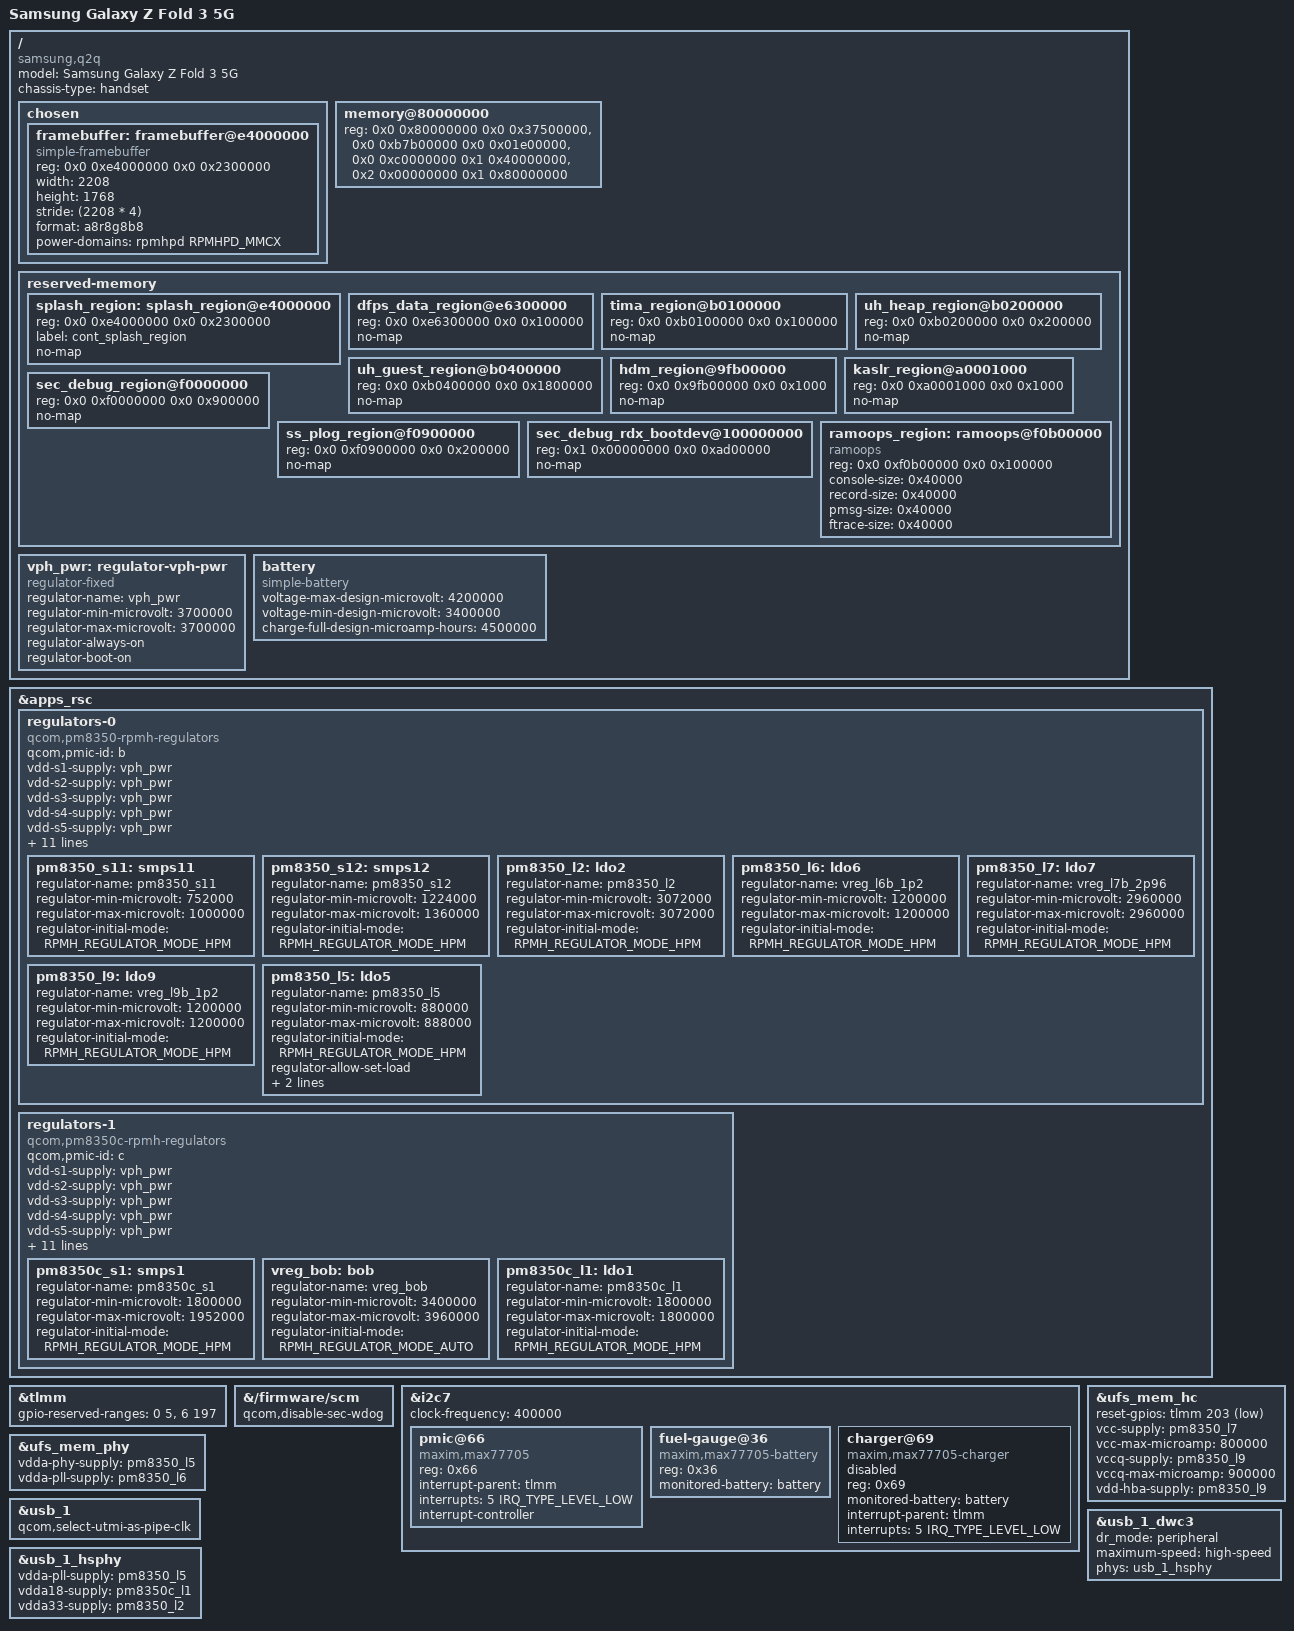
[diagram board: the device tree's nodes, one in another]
// SPDX-License-Identifier: BSD-3-Clause
/*
 * Samsung Galaxy Z Fold 3 5G (SM-F926B, codename q2q)
 * SoC: Qualcomm SM8350 (lahaina)
 *
 * STAGE 1: deliberately minimal. Boots to an initramfs with a framebuffer
 * console and USB gadget, nothing else. UFS, DSI, Wi-Fi, audio and the
 * remoteprocs all come later -- the point of this file is the smallest thing
 * that can possibly boot, so that a failure has few candidate causes.
 *
 * Modelled on two upstream files:
 *   sm8350-sony-xperia-sagami.dtsi  -- correct SM8350 rails and PMIC labels
 *   sm8450-samsung-r0q.dts          -- Samsung conventions (splash_region, USB 2.0)
 *
 * Board data was read off the device on 2026-11-07, not guessed:
 *   /memory             the four ranges ABL itself publishes (11.90 GiB, 12 GB unit)
 *   reserved-memory     37 regions from the merged post-ABL DT
 *   framebuffer         cont_splash_region + the S6E3XA2 panel timings
 *   ro.revision = 9  ->  board DTS revision r08 is authoritative for this unit
 *
 * NOT BOOTED. NOT TESTED. See dts-work/README.md.
 */

/dts-v1/;

#include <dt-bindings/gpio/gpio.h>
#include <dt-bindings/interrupt-controller/arm-gic.h>
#include <dt-bindings/regulator/qcom,rpmh-regulator.h>

#include "sm8350.dtsi"
#include "pm8350.dtsi"
#include "pm8350c.dtsi"

/ {
	model = "Samsung Galaxy Z Fold 3 5G";
	compatible = "samsung,q2q", "qcom,sm8350";
	chassis-type = "handset";

	/*
	 * ABL hands us no command line (uniLoader owns it, and the stock one is
	 * console=null anyway), so force our own in the kernel config with
	 * CONFIG_CMDLINE_FORCE.
	 */
	chosen {
		#address-cells = <2>;
		#size-cells = <2>;
		ranges;

		/*
		 * The bootloader's continuous-splash surface. Lets us have a visible
		 * console with no display driver at all -- there is no UART on this
		 * device, so this is the primary debug output for first boot.
		 *
		 * The inner panel is NATIVELY LANDSCAPE (2208x1768). Text will appear
		 * rotated relative to how the device is held; that is expected.
		 */
		framebuffer: framebuffer@e4000000 {
			compatible = "simple-framebuffer";
			reg = <0x0 0xe4000000 0x0 0x2300000>;
			width = <2208>;
			height = <1768>;
			stride = <(2208 * 4)>;
			format = "a8r8g8b8";

			/*
			 * Hold the display power domain up.
			 *
			 * The Galaxy Tab S8+ port warns that simplefb needs `clocks`
			 * and `power-domains` or the bootloader's scanout gets torn
			 * down. Only half of that applies to us:
			 *
			 *  - clocks: deliberately NOT claimed. SM_DISPCC_8250 is built
			 *    out for Stage 1 (built in, it reprograms the display
			 *    clocks and garbles the live scanout -- observed). With no
			 *    clock driver loaded there is nothing to gate those clocks,
			 *    so the bootloader's state simply persists. Referencing
			 *    dispcc here would point at a provider that never probes
			 *    and simpledrm would defer forever.
			 *
			 *  - power-domains: this one is real. QCOM_RPMHPD is built in,
			 *    and if nothing claims MMCX the domain can be dropped to
			 *    its minimum corner, cutting display power out from under
			 *    us. So we claim it.
			 */
			power-domains = <&rpmhpd RPMHPD_MMCX>;
		};
	};

	/*
	 * Explicit memory node. uniLoader carries this DT and ABL never rewrites
	 * it, so nothing will fill this in for us.
	 *
	 * These are the exact four ranges ABL publishes to the stock kernel,
	 * read out of the merged post-ABL DT:
	 *   0x080000000 + 0x37500000    893 MiB
	 *   0x0b7b00000 + 0x01e00000     30 MiB
	 *   0x0c0000000 + 0x140000000     5 GiB
	 *   0x200000000 + 0x180000000     6 GiB   = 11.90 GiB total
	 *
	 * Cross-checked: /proc/iomem on the stock kernel reports 11.41 GiB usable
	 * after carve-outs, which is consistent.
	 *
	 * (Worth noting: both the Galaxy S22 port and U-Boot's Qualcomm docs warn
	 * that Samsung bootloaders can emit a bogus or zero-sized memory node.
	 * On this device ABL's memory node is sane. Its *demura_region_0/1*
	 * reserved nodes ARE zero-sized, so the warning is not baseless -- it just
	 * does not apply to /memory here.)
	 */
	memory@80000000 {
		device_type = "memory";
		reg = <0x0 0x80000000 0x0 0x37500000>,
		      <0x0 0xb7b00000 0x0 0x01e00000>,
		      <0x0 0xc0000000 0x1 0x40000000>,
		      <0x2 0x00000000 0x1 0x80000000>;
	};

	reserved-memory {
		/*
		 * Samsung-specific carve-outs that sm8350.dtsi does not know about.
		 * The generic Qualcomm regions (hyp, xbl_aop, smem, cpucp_fw,
		 * cdsp_secure_heap, pil_*, rmtfs, removed, qrtr_shbuf, chan*_shbuf)
		 * are inherited from sm8350.dtsi unchanged -- verified to match
		 * lahaina.dtsi's own values, so upstream is already correct for this
		 * device and must NOT be overridden.
		 */

		/*
		 * Naming here is genuinely ambiguous and worth knowing about.
		 *
		 * Upstream sm8450-samsung-r0q.dts carries the comment "the bootloader
		 * will only keep display hardware enabled if this memory region is
		 * named exactly 'splash_region'" -- and then writes the node as
		 * "splash-region@b8000000", with a hyphen. It contradicts itself.
		 * Samsung's own DT on this device uses "splash_region" (underscore, no
		 * unit address) plus label = "cont_splash_region".
		 *
		 * For OUR boot path it does not matter: uniLoader presents itself to
		 * ABL as a kernel, so ABL never parses this DT at all. The only job
		 * this node has is stopping Linux from allocating over the framebuffer.
		 * We keep the underscore (matching both the stated requirement and
		 * Samsung) and add a unit address so dtc stays quiet.
		 *
		 * If we ever boot WITHOUT uniLoader -- e.g. the Galaxy M52 approach of
		 * injecting a DT into vendor_boot, where ABL does read it -- and the
		 * display dies, try renaming this to bare "splash_region" first.
		 */
		splash_region: splash_region@e4000000 {
			reg = <0x0 0xe4000000 0x0 0x2300000>;
			label = "cont_splash_region";
			no-map;
		};

		dfps_data_region@e6300000 {
			reg = <0x0 0xe6300000 0x0 0x100000>;
			no-map;
		};

		/*
		 * Samsung TrustZone / "Universal Hypervisor" (RKP). Installed by the
		 * bootloader before any kernel runs, so this memory is occupied no
		 * matter whose kernel boots. Touching it faults.
		 */
		tima_region@b0100000 {
			reg = <0x0 0xb0100000 0x0 0x100000>;
			no-map;
		};

		uh_heap_region@b0200000 {
			reg = <0x0 0xb0200000 0x0 0x200000>;
			no-map;
		};

		uh_guest_region@b0400000 {
			reg = <0x0 0xb0400000 0x0 0x1800000>;
			no-map;
		};

		hdm_region@9fb00000 {
			reg = <0x0 0x9fb00000 0x0 0x1000>;
			no-map;
		};

		/* Where ABL leaves the KASLR seed. */
		kaslr_region@a0001000 {
			reg = <0x0 0xa0001000 0x0 0x1000>;
			no-map;
		};

		/* Samsung debug areas. Reserved so the kernel does not reuse them. */
		sec_debug_region@f0000000 {
			reg = <0x0 0xf0000000 0x0 0x900000>;
			no-map;
		};

		ss_plog_region@f0900000 {
			reg = <0x0 0xf0900000 0x0 0x200000>;
			no-map;
		};

		sec_debug_rdx_bootdev@100000000 {
			reg = <0x1 0x00000000 0x0 0xad00000>;
			no-map;
		};

		/*
		 * ramoops. With no UART, this is the only way to read a panic from
		 * the *previous* boot, so it is worth having from day one.
		 * Deliberately NOT no-map: pstore has to be able to map it.
		 */
		ramoops_region: ramoops@f0b00000 {
			compatible = "ramoops";
			reg = <0x0 0xf0b00000 0x0 0x100000>;
			/*
			 * Mirrors Samsung's own ramoops node byte for byte: four
			 * 256 KiB zones filling the 1 MiB region, and NO ecc-size.
			 *
			 * The first version of this node asked for 512/256/128/128
			 * plus ecc-size = 16. The zones alone already filled the
			 * region exactly, so the ECC data had nowhere to live and the
			 * driver did not probe -- /sys/fs/pstore came back empty after
			 * a run we KNOW executed. Without a UART this is our only
			 * black box, so it has to actually work.
			 */
			console-size = <0x40000>;
			record-size  = <0x40000>;
			pmsg-size    = <0x40000>;
			ftrace-size  = <0x40000>;
		};
	};

	vph_pwr: regulator-vph-pwr {
		compatible = "regulator-fixed";
		regulator-name = "vph_pwr";
		regulator-min-microvolt = <3700000>;
		regulator-max-microvolt = <3700000>;
		regulator-always-on;
		regulator-boot-on;
	};
};

/*
 * Regulators. Minimal on purpose: only the rails the USB HS PHY needs, plus
 * their parents. Voltages are taken verbatim from upstream
 * sm8350-sony-xperia-sagami.dtsi -- these are PMIC-level constraints on the
 * same PMICs at the same rails, so they transfer.
 */
&apps_rsc {
	regulators-0 {
		compatible = "qcom,pm8350-rpmh-regulators";
		qcom,pmic-id = "b";

		vdd-s1-supply = <&vph_pwr>;
		vdd-s2-supply = <&vph_pwr>;
		vdd-s3-supply = <&vph_pwr>;
		vdd-s4-supply = <&vph_pwr>;
		vdd-s5-supply = <&vph_pwr>;
		vdd-s6-supply = <&vph_pwr>;
		vdd-s7-supply = <&vph_pwr>;
		vdd-s8-supply = <&vph_pwr>;
		vdd-s9-supply = <&vph_pwr>;
		vdd-s10-supply = <&vph_pwr>;
		vdd-s11-supply = <&vph_pwr>;
		vdd-s12-supply = <&vph_pwr>;

		vdd-l1-l4-supply = <&pm8350_s11>;
		vdd-l2-l7-supply = <&vreg_bob>;
		vdd-l3-l5-supply = <&vreg_bob>;
		vdd-l6-l9-l10-supply = <&pm8350_s11>;

		/*
		 * ARC regulators (not described here):
		 *   S5 - mx.lvl   S6 - gfx.lvl   S9 - mxc.lvl
		 */

		pm8350_s11: smps11 {
			regulator-name = "pm8350_s11";
			regulator-min-microvolt = <752000>;
			regulator-max-microvolt = <1000000>;
			regulator-initial-mode = <RPMH_REGULATOR_MODE_HPM>;
		};

		pm8350_s12: smps12 {
			regulator-name = "pm8350_s12";
			regulator-min-microvolt = <1224000>;
			regulator-max-microvolt = <1360000>;
			regulator-initial-mode = <RPMH_REGULATOR_MODE_HPM>;
		};

		/* USB HS PHY vdda33 */
		pm8350_l2: ldo2 {
			regulator-name = "pm8350_l2";
			regulator-min-microvolt = <3072000>;
			regulator-max-microvolt = <3072000>;
			regulator-initial-mode = <RPMH_REGULATOR_MODE_HPM>;
		};

		/* USB HS PHY vdda-pll */
		/* UFS PHY PLL. Rail assignment matches sm8350-hdk/mtp/surface-duo2. */
		pm8350_l6: ldo6 {
			regulator-name = "vreg_l6b_1p2";
			regulator-min-microvolt = <1200000>;
			regulator-max-microvolt = <1200000>;
			regulator-initial-mode = <RPMH_REGULATOR_MODE_HPM>;
		};

		/* UFS vcc, the device's main 2.96 V rail. */
		pm8350_l7: ldo7 {
			regulator-name = "vreg_l7b_2p96";
			regulator-min-microvolt = <2960000>;
			regulator-max-microvolt = <2960000>;
			regulator-initial-mode = <RPMH_REGULATOR_MODE_HPM>;
		};

		/* UFS vccq + vdd-hba. */
		pm8350_l9: ldo9 {
			regulator-name = "vreg_l9b_1p2";
			regulator-min-microvolt = <1200000>;
			regulator-max-microvolt = <1200000>;
			regulator-initial-mode = <RPMH_REGULATOR_MODE_HPM>;
		};

		pm8350_l5: ldo5 {
			regulator-name = "pm8350_l5";
			regulator-min-microvolt = <880000>;
			regulator-max-microvolt = <888000>;
			regulator-initial-mode = <RPMH_REGULATOR_MODE_HPM>;
			regulator-allow-set-load;
			regulator-allowed-modes = <RPMH_REGULATOR_MODE_LPM
						   RPMH_REGULATOR_MODE_HPM>;
		};
	};

	regulators-1 {
		compatible = "qcom,pm8350c-rpmh-regulators";
		qcom,pmic-id = "c";

		vdd-s1-supply = <&vph_pwr>;
		vdd-s2-supply = <&vph_pwr>;
		vdd-s3-supply = <&vph_pwr>;
		vdd-s4-supply = <&vph_pwr>;
		vdd-s5-supply = <&vph_pwr>;
		vdd-s6-supply = <&vph_pwr>;
		vdd-s7-supply = <&vph_pwr>;
		vdd-s8-supply = <&vph_pwr>;
		vdd-s9-supply = <&vph_pwr>;
		vdd-s10-supply = <&vph_pwr>;

		vdd-l1-l12-supply = <&pm8350c_s1>;
		vdd-l2-l8-supply = <&pm8350c_s1>;
		vdd-l3-l4-l5-l7-l13-supply = <&vreg_bob>;
		vdd-l6-l9-l11-supply = <&vreg_bob>;
		vdd-l10-supply = <&pm8350_s12>;
		vdd-bob-supply = <&vph_pwr>;

		pm8350c_s1: smps1 {
			regulator-name = "pm8350c_s1";
			regulator-min-microvolt = <1800000>;
			regulator-max-microvolt = <1952000>;
			regulator-initial-mode = <RPMH_REGULATOR_MODE_HPM>;
		};

		vreg_bob: bob {
			regulator-name = "vreg_bob";
			regulator-min-microvolt = <3400000>;
			regulator-max-microvolt = <3960000>;
			regulator-initial-mode = <RPMH_REGULATOR_MODE_AUTO>;
		};

		/* USB HS PHY vdda18 */
		pm8350c_l1: ldo1 {
			regulator-name = "pm8350c_l1";
			regulator-min-microvolt = <1800000>;
			regulator-max-microvolt = <1800000>;
			regulator-initial-mode = <RPMH_REGULATOR_MODE_HPM>;
		};
	};
};

/*
 * TLMM: reserve EVERY gpio.
 *
 * sm8350-tlmm probe is where boot hangs. dyndbg caught it exactly:
 *   platform f100000.pinctrl: really_probe: probing driver sm8350-tlmm
 *   <no driver_bound, no "probe of ... returned" -- it never comes back>
 *
 * gpiochip_add_data() calls ->get_direction() per line, but only where
 * gpiochip_line_is_valid() (gpiolib.c:1316). On Samsung devices the secure
 * world owns some TLMM lines and reading their config register hangs the
 * bus. gpio-reserved-ranges clears those bits so the read never happens.
 *
 * Every other SM8350 board upstream sets this and ours did not:
 *   sm8350-hdk / sm8350-mtp      <52 8>
 *   sony-xperia-sagami           <44 4>
 *   microsoft-surface-duo2       <4 4>, <12 4>, <56 4>, <76 4>
 *
 * The real q2q set is unknown, and the values above disagree, so this is
 * deliberately ALL 204 lines: Stage 1 needs no GPIO whatsoever, and a total
 * reserve turns "which lines are protected?" into a yes/no question. Once
 * boot gets past tlmm, bisect this down to the true set.
 */
&tlmm {
	/*
	 * 203 of 204 lines stay reserved. GPIO 203 is the UFS reset, and every
	 * upstream SM8350 board that has working UFS drives it:
	 *   sm8350-hdk / mtp / surface-duo2:  reset-gpios = <&tlmm 203 ...>
	 * Freeing one line at a time keeps the blanket reserve honest until the
	 * genuinely TZ-owned set is known.
	 *
	 * GPIO 5 is additionally freed for the max77705 charger interrupt.
	 * Reserved: 0-4 and 6-202.  Free: 5 and 203.
	 */
	gpio-reserved-ranges = <0 5>, <6 197>;
};

/*
 * Battery profile. This is the only thing the mainline max77705 charger reads
 * from DT, and it is deliberately CONSERVATIVE.
 *
 * Samsung's own q2q values, for reference:
 *     battery,chg_float_voltage   = 4440 mV
 *     battery,max_charging_current= 3000 mA
 *     battery,battery_full_capacity = 4500 mAh
 *     battery,chg_high_temp       = 49.0 C  (recovery 47.0 C)
 *
 * We use 4.2 V instead of 4.44 V. max77705_charger_initialize() feeds
 * voltage-max-design-microvolt straight into max77705_set_float_voltage()
 * (drivers/power/supply/max77705_charger.c:562), so this caps the pack at
 * roughly 75-80% of its rated capacity. For a device that mostly sits on a
 * bench that is strictly better: far from the cell's stress region, and much
 * kinder to a battery we cannot replace.
 *
 * Charge CURRENT is not taken from DT at all -- the driver leaves the chip at
 * its 450 mA hardware default, which is 0.1C into a 4500 mAh pack. Gentle,
 * and well under the 500 mA-1 A band we agreed on.
 *
 * Both cells stay connected and no limiter is touched.
 */
/ {
	battery: battery {
		compatible = "simple-battery";
		voltage-max-design-microvolt = <4200000>;
		voltage-min-design-microvolt = <3400000>;
		charge-full-design-microamp-hours = <4500000>;
	};
};

/*
 * Ask SCM to deactivate the bootloader's secure watchdog.
 *
 * The APSS watchdog block is unreachable by MMIO (see below), but Samsung's
 * own kernel never touches it directly either -- it goes through TrustZone:
 *   drivers/soc/qcom/qcom_wdt_core.c:550  qcom_scm_sec_wdog_deactivate()
 *   SVC 0x01 (BOOT) / CMD 0x07 / owner SIP / args[0] = 1
 *
 * Mainline's qcom_scm has no 0x07 command at all, so it has been patched in
 * (patches/0001-qcom_scm-sec-wdog-deactivate.patch). This property opts us in.
 */
&{/firmware/scm} {
	qcom,disable-sec-wdog;
};

/*
 * NO watchdog node. The APSS watchdog block at 0x17c10000 is UNREACHABLE from
 * the non-secure world on this device.
 *
 * Proven twice, from two different execution contexts:
 *   - uniLoader late_init read/wrote 0x17c10008 in bare metal: attempts 7 and
 *     8 died there with a blackscreen, before Linux ever started.
 *   - qcom_wdt_probe's readl() of WDT_STS/WDT_EN took a synchronous external
 *     abort (ESR 0000000096000010, DFSC 0x10 -- the bus refused it, the MMU
 *     mapping was fine), panicking init:
 *         pc : qcom_wdt_probe+0x338/0x3cc
 *         Kernel panic - not syncing: Attempted to kill init!
 *
 * Samsung's downstream DT does carry qcom,wdt@17c10000 and their kernel uses
 * it, so the block is presumably unlocked for them by firmware we do not
 * invoke. Until that handshake is understood, nothing may touch this address.
 *
 * Consequence: the watchdog stays armed and we cannot pet it. Stage 1 has to
 * complete inside its bite window.
 */

/*
 * UFS stays off for Stage 1. Note upstream sagami also disables it, so SM8350
 * UFS is not a solved problem in mainline yet (a patch enabling it on sagami
 * was under review as of 2026). We boot from an initramfs instead, which
 * removes storage from the list of things that can go wrong on first boot.
 */
/*
 * max77705 PMIC / charger, on qupv3_se7_i2c (i2c@99c000) per the merged
 * post-ABL DT we pulled off the device. Two slave addresses on one chip:
 * 0x66 is the MFD, 0x69 is the charger. IRQ is TLMM GPIO 5, which is why
 * that line had to come out of gpio-reserved-ranges above.
 */
&i2c7 {
	status = "okay";
	clock-frequency = <400000>;

	pmic@66 {
		compatible = "maxim,max77705";
		reg = <0x66>;
		interrupt-parent = <&tlmm>;
		interrupts = <5 IRQ_TYPE_LEVEL_LOW>;
		interrupt-controller;
		#interrupt-cells = <1>;
	};

	/*
	 * Fuel gauge. Mainline's max17042_battery already lists
	 * "maxim,max77705-battery", so no new driver is needed.
	 *
	 * READ-ONLY BY CONSTRUCTION: max17042_init_chip() only runs when
	 * (enable_por_init && config_data), and we supply no maxim,config-data
	 * in DT -- so the driver never reprograms the gauge's model or
	 * learned capacity. It only reads.
	 *
	 * No interrupt wired: the ALRT pin would mean freeing another GPIO,
	 * and polling is perfectly adequate for a percentage readout.
	 *
	 * 0x36 is the Maxim ModelGauge convention (8-bit 0x6c >> 1), matching
	 * how the charger sits at 0x69 (8-bit 0xd2 >> 1).
	 */
	fuel-gauge@36 {
		compatible = "maxim,max77705-battery";
		reg = <0x36>;
		monitored-battery = <&battery>;
	};

	/*
	 * Charger node kept but DISABLED. CONFIG_CHARGER_MAX77705 is off too,
	 * so this binds nothing either way -- it is here so re-enabling is a
	 * one-line change once the s2asl01 limiters can be read. See the
	 * config fragment for why.
	 */
	charger@69 {
		compatible = "maxim,max77705-charger";
		reg = <0x69>;
		monitored-battery = <&battery>;
		interrupt-parent = <&tlmm>;
		interrupts = <5 IRQ_TYPE_LEVEL_LOW>;
		status = "disabled";
	};
};

/*
 * UFS. Off for Stage 1; on now because it is the last piece of a hands-free
 * flash loop -- with storage the shell can dd a new boot.img onto the boot
 * partition itself, and "poweroff -f" power-cycles straight into it (VBUS
 * present makes ABL power the device back on). No buttons, no Download Mode.
 *
 * Supplies and the reset line follow sm8350-hdk / mtp / surface-duo2, which
 * all agree. Sony sagami disables UFS, so it is no help here.
 */
&ufs_mem_hc {
	status = "okay";

	reset-gpios = <&tlmm 203 GPIO_ACTIVE_LOW>;

	vcc-supply = <&pm8350_l7>;
	vcc-max-microamp = <800000>;
	vccq-supply = <&pm8350_l9>;
	vccq-max-microamp = <900000>;
	vdd-hba-supply = <&pm8350_l9>;
};

&ufs_mem_phy {
	status = "okay";

	vdda-phy-supply = <&pm8350_l5>;
	vdda-pll-supply = <&pm8350_l6>;
};

/*
 * USB 2.0, peripheral only -- the same deliberate reduction upstream
 * sm8450-samsung-r0q.dts makes. Gives us a USB gadget (and therefore networking
 * and a shell) without bringing up the SS PHY.
 */
&usb_1 {
	/*
	 * Glue node (qcom,sm8350-dwc3). With no SuperSpeed PHY in play, the glue
	 * must take UTMI as its pipe clock.
	 */
	qcom,select-utmi-as-pipe-clk;

	status = "okay";
};

&usb_1_dwc3 {
	/*
	 * Core node (snps,dwc3). phys/phy-names live HERE, not on the glue --
	 * sm8350.dtsi declares them on this node. Overriding them on &usb_1
	 * silently does nothing and leaves usb3-phy attached, which is exactly
	 * the mistake the first draft of this file made.
	 *
	 * (Upstream sm8450-samsung-r0q.dts sets dr_mode, maximum-speed and phys
	 * on &usb_1. Upstream sm8350-sony-xperia-sagami.dtsi sets dr_mode on
	 * &usb_1_dwc3. We follow sagami: same SoC, and it matches where
	 * sm8350.dtsi actually declares the properties.)
	 */
	dr_mode = "peripheral";
	maximum-speed = "high-speed";

	/* drop the SuperSpeed PHY */
	phys = <&usb_1_hsphy>;
	phy-names = "usb2-phy";
};

&usb_1_hsphy {
	vdda-pll-supply = <&pm8350_l5>;
	vdda18-supply = <&pm8350c_l1>;
	vdda33-supply = <&pm8350_l2>;

	status = "okay";
};
